AUTOSAR XML (schema 4-2-2)
package /COM_SWC
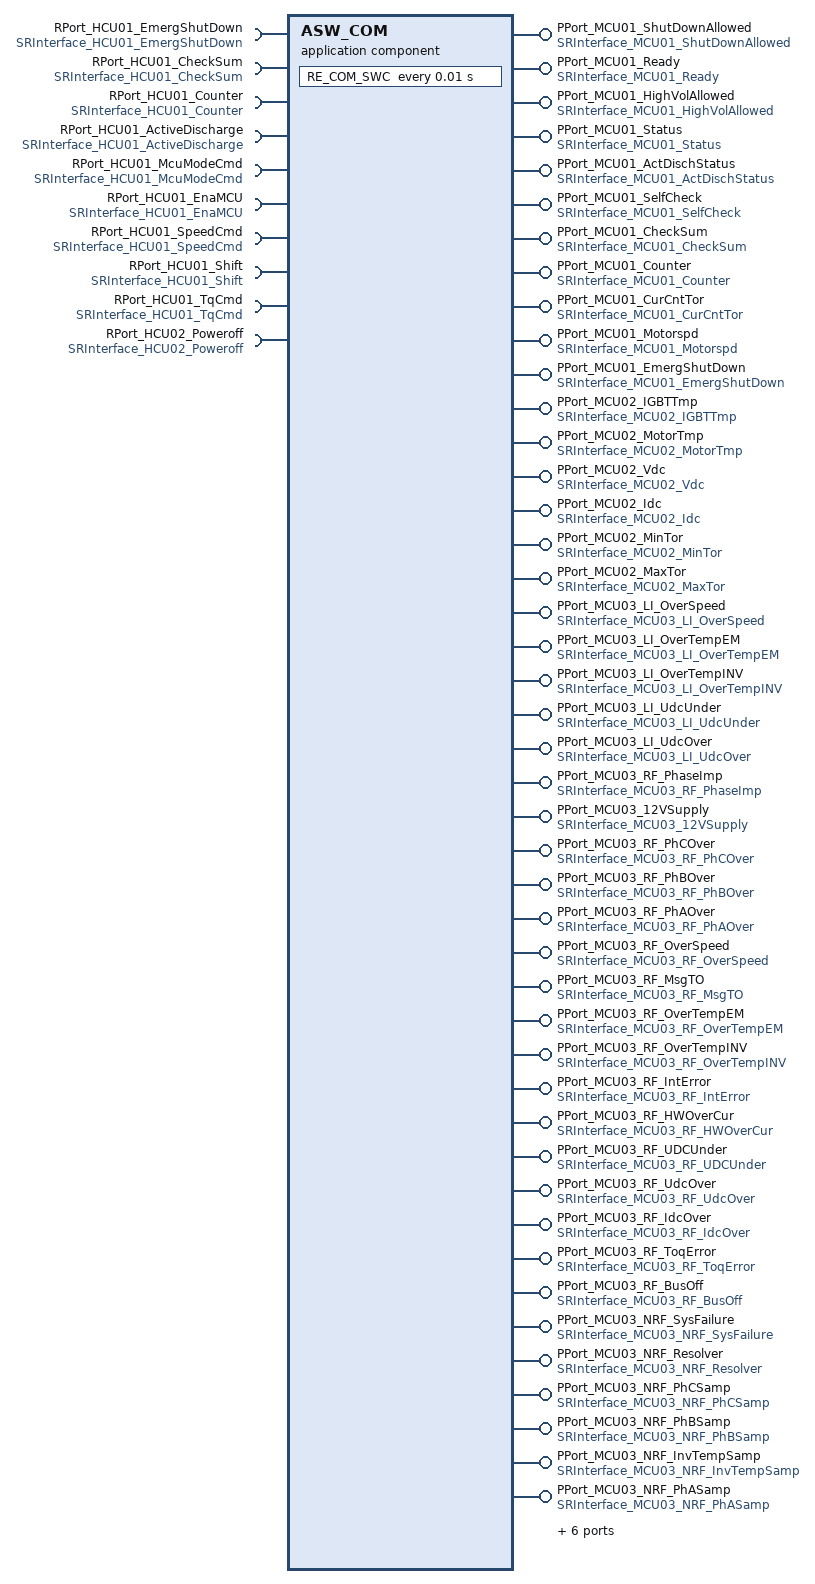
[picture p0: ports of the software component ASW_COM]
  application sw component type ASW_COM
    10 x require port:
      RPort_HCU01_EmergShutDown: nonqueued-receiver-com-spec{data-element=HCU01_EmergShutDown, alive-timeout=0.5}, required-interface=SRInterface_HCU01_EmergShutDown
      RPort_HCU01_CheckSum: nonqueued-receiver-com-spec{data-element=HCU01_CheckSum, alive-timeout=0.5}, required-interface=SRInterface_HCU01_CheckSum
      RPort_HCU01_Counter: nonqueued-receiver-com-spec{data-element=HCU01_Counter, alive-timeout=0.5}, required-interface=SRInterface_HCU01_Counter
      RPort_HCU01_ActiveDischarge: nonqueued-receiver-com-spec{data-element=HCU01_ActiveDischarge, alive-timeout=0.5}, required-interface=SRInterface_HCU01_ActiveDischarge
      RPort_HCU01_McuModeCmd: nonqueued-receiver-com-spec{data-element=HCU01_McuModeCmd, alive-timeout=0.5}, required-interface=SRInterface_HCU01_McuModeCmd
      RPort_HCU01_EnaMCU: nonqueued-receiver-com-spec{data-element=HCU01_EnaMCU, alive-timeout=0.5}, required-interface=SRInterface_HCU01_EnaMCU
      RPort_HCU01_SpeedCmd: nonqueued-receiver-com-spec{data-element=HCU01_SpeedCmd, alive-timeout=0.5}, required-interface=SRInterface_HCU01_SpeedCmd
      RPort_HCU01_Shift: nonqueued-receiver-com-spec{data-element=HCU01_Shift, alive-timeout=0.5}, required-interface=SRInterface_HCU01_Shift
      RPort_HCU01_TqCmd: nonqueued-receiver-com-spec{data-element=HCU01_TqCmd, alive-timeout=0.5}, required-interface=SRInterface_HCU01_TqCmd
      RPort_HCU02_Poweroff: nonqueued-receiver-com-spec{data-element=HCU02_Poweroff, alive-timeout=0.5}, required-interface=SRInterface_HCU02_Poweroff
    50 x provide port:
      PPort_MCU01_ShutDownAllowed: provided-interface=SRInterface_MCU01_ShutDownAllowed
      PPort_MCU01_Ready: provided-interface=SRInterface_MCU01_Ready
      PPort_MCU01_HighVolAllowed: provided-interface=SRInterface_MCU01_HighVolAllowed
      PPort_MCU01_Status: provided-interface=SRInterface_MCU01_Status
      PPort_MCU01_ActDischStatus: provided-interface=SRInterface_MCU01_ActDischStatus
      PPort_MCU01_SelfCheck: provided-interface=SRInterface_MCU01_SelfCheck
      PPort_MCU01_CheckSum: provided-interface=SRInterface_MCU01_CheckSum
      PPort_MCU01_Counter: provided-interface=SRInterface_MCU01_Counter
      PPort_MCU01_CurCntTor: provided-interface=SRInterface_MCU01_CurCntTor
      PPort_MCU01_Motorspd: provided-interface=SRInterface_MCU01_Motorspd
      PPort_MCU01_EmergShutDown: provided-interface=SRInterface_MCU01_EmergShutDown
      PPort_MCU02_IGBTTmp: provided-interface=SRInterface_MCU02_IGBTTmp
      PPort_MCU02_MotorTmp: provided-interface=SRInterface_MCU02_MotorTmp
      PPort_MCU02_Vdc: provided-interface=SRInterface_MCU02_Vdc
      PPort_MCU02_Idc: provided-interface=SRInterface_MCU02_Idc
      PPort_MCU02_MinTor: provided-interface=SRInterface_MCU02_MinTor
      PPort_MCU02_MaxTor: provided-interface=SRInterface_MCU02_MaxTor
      PPort_MCU03_LI_OverSpeed: provided-interface=SRInterface_MCU03_LI_OverSpeed
      PPort_MCU03_LI_OverTempEM: provided-interface=SRInterface_MCU03_LI_OverTempEM
      PPort_MCU03_LI_OverTempINV: provided-interface=SRInterface_MCU03_LI_OverTempINV
      PPort_MCU03_LI_UdcUnder: provided-interface=SRInterface_MCU03_LI_UdcUnder
      PPort_MCU03_LI_UdcOver: provided-interface=SRInterface_MCU03_LI_UdcOver
      PPort_MCU03_RF_PhaseImp: provided-interface=SRInterface_MCU03_RF_PhaseImp
      PPort_MCU03_12VSupply: provided-interface=SRInterface_MCU03_12VSupply
      PPort_MCU03_RF_PhCOver: provided-interface=SRInterface_MCU03_RF_PhCOver
      PPort_MCU03_RF_PhBOver: provided-interface=SRInterface_MCU03_RF_PhBOver
      PPort_MCU03_RF_PhAOver: provided-interface=SRInterface_MCU03_RF_PhAOver
      PPort_MCU03_RF_OverSpeed: provided-interface=SRInterface_MCU03_RF_OverSpeed
      PPort_MCU03_RF_MsgTO: provided-interface=SRInterface_MCU03_RF_MsgTO
      PPort_MCU03_RF_OverTempEM: provided-interface=SRInterface_MCU03_RF_OverTempEM
      PPort_MCU03_RF_OverTempINV: provided-interface=SRInterface_MCU03_RF_OverTempINV
      PPort_MCU03_RF_IntError: provided-interface=SRInterface_MCU03_RF_IntError
      PPort_MCU03_RF_HWOverCur: provided-interface=SRInterface_MCU03_RF_HWOverCur
      PPort_MCU03_RF_UDCUnder: provided-interface=SRInterface_MCU03_RF_UDCUnder
      PPort_MCU03_RF_UdcOver: provided-interface=SRInterface_MCU03_RF_UdcOver
      PPort_MCU03_RF_IdcOver: provided-interface=SRInterface_MCU03_RF_IdcOver
      PPort_MCU03_RF_ToqError: provided-interface=SRInterface_MCU03_RF_ToqError
      PPort_MCU03_RF_BusOff: provided-interface=SRInterface_MCU03_RF_BusOff
      PPort_MCU03_NRF_SysFailure: provided-interface=SRInterface_MCU03_NRF_SysFailure
      PPort_MCU03_NRF_Resolver: provided-interface=SRInterface_MCU03_NRF_Resolver
      PPort_MCU03_NRF_PhCSamp: provided-interface=SRInterface_MCU03_NRF_PhCSamp
      PPort_MCU03_NRF_PhBSamp: provided-interface=SRInterface_MCU03_NRF_PhBSamp
      PPort_MCU03_NRF_InvTempSamp: provided-interface=SRInterface_MCU03_NRF_InvTempSamp
      PPort_MCU03_NRF_PhASamp: provided-interface=SRInterface_MCU03_NRF_PhASamp
      PPort_MCU03_NRF_DESAT: provided-interface=SRInterface_MCU03_NRF_DESAT
      PPort_MCU03_NRF_UdcSamp: provided-interface=SRInterface_MCU03_NRF_UdcSamp
      PPort_MCU03_NRF_COMError: provided-interface=SRInterface_MCU03_NRF_COMError
      PPort_MCU03_NRF_5VSupply: provided-interface=SRInterface_MCU03_NRF_5VSupply
      PPort_MCU03_NRF_EMTempSamp: provided-interface=SRInterface_MCU03_NRF_EMTempSamp
      PPort_MCU03_NRF_IdcSamp: provided-interface=SRInterface_MCU03_NRF_IdcSamp
    behavior IB_swc_COM
      timing event TE_SWC_COM_10ms: start-on-event=RE_COM_SWC, period=0.01
      runnable RE_COM_SWC: symbol=RE_COM_SWC_func
        data-receive-point-by-arguments:
          10 x access:
            DRWA_HCU01_EmergShutDown: accessed-variable=RPort_HCU01_EmergShutDown.HCU01_EmergShutDown
            DRWA_HCU01_CheckSum: accessed-variable=RPort_HCU01_CheckSum.HCU01_CheckSum
            DRWA_HCU01_Counter: accessed-variable=RPort_HCU01_Counter.HCU01_Counter
            DRWA_HCU01_ActiveDischarge: accessed-variable=RPort_HCU01_ActiveDischarge.HCU01_ActiveDischarge
            DRWA_HCU01_McuModeCmd: accessed-variable=RPort_HCU01_McuModeCmd.HCU01_McuModeCmd
            DRWA_HCU01_EnaMCU: accessed-variable=RPort_HCU01_EnaMCU.HCU01_EnaMCU
            DRWA_HCU01_SpeedCmd: accessed-variable=RPort_HCU01_SpeedCmd.HCU01_SpeedCmd
            DRWA_HCU01_Shift: accessed-variable=RPort_HCU01_Shift.HCU01_Shift
            DRWA_HCU01_TqCmd: accessed-variable=RPort_HCU01_TqCmd.HCU01_TqCmd
            DRWA_HCU02_Poweroff: accessed-variable=RPort_HCU02_Poweroff.HCU02_Poweroff
        data-send-points:
          50 x access:
            DSP_MCU01_ShutDownAllowed: accessed-variable=PPort_MCU01_ShutDownAllowed.MCU01_ShutDownAllowed
            DSP_MCU01_Ready: accessed-variable=PPort_MCU01_Ready.MCU01_Ready
            DSP_MCU01_HighVolAllowed: accessed-variable=PPort_MCU01_HighVolAllowed.MCU01_HighVolAllowed
            DSP_MCU01_Status: accessed-variable=PPort_MCU01_Status.MCU01_Status
            DSP_MCU01_ActDischStatus: accessed-variable=PPort_MCU01_ActDischStatus.MCU01_ActDischStatus
            DSP_MCU01_SelfCheck: accessed-variable=PPort_MCU01_SelfCheck.MCU01_SelfCheck
            DSP_MCU01_CheckSum: accessed-variable=PPort_MCU01_CheckSum.MCU01_CheckSum
            DSP_MCU01_Counter: accessed-variable=PPort_MCU01_Counter.MCU01_Counter
            DSP_MCU01_CurCntTor: accessed-variable=PPort_MCU01_CurCntTor.MCU01_CurCntTor
            DSP_MCU01_Motorspd: accessed-variable=PPort_MCU01_Motorspd.MCU01_Motorspd
            DSP_MCU01_EmergShutDown: accessed-variable=PPort_MCU01_EmergShutDown.MCU01_EmergShutDown
            DSP_MCU02_IGBTTmp: accessed-variable=PPort_MCU02_IGBTTmp.MCU02_IGBTTmp
            DSP_MCU02_MotorTmp: accessed-variable=PPort_MCU02_MotorTmp.MCU02_MotorTmp
            DSP_MCU02_Vdc: accessed-variable=PPort_MCU02_Vdc.MCU02_Vdc
            DSP_MCU02_Idc: accessed-variable=PPort_MCU02_Idc.MCU02_Idc
            DSP_MCU02_MinTor: accessed-variable=PPort_MCU02_MinTor.MCU02_MinTor
            DSP_MCU02_MaxTor: accessed-variable=PPort_MCU02_MaxTor.MCU02_MaxTor
            DSP_MCU03_LI_OverSpeed: accessed-variable=PPort_MCU03_LI_OverSpeed.MCU03_LI_OverSpeed
            DSP_MCU03_LI_OverTempEM: accessed-variable=PPort_MCU03_LI_OverTempEM.MCU03_LI_OverTempEM
            DSP_MCU03_LI_OverTempINV: accessed-variable=PPort_MCU03_LI_OverTempINV.MCU03_LI_OverTempINV
            DSP_MCU03_LI_UdcUnder: accessed-variable=PPort_MCU03_LI_UdcUnder.MCU03_LI_UdcUnder
            DSP_MCU03_LI_UdcOver: accessed-variable=PPort_MCU03_LI_UdcOver.MCU03_LI_UdcOver
            DSP_MCU03_RF_PhaseImp: accessed-variable=PPort_MCU03_RF_PhaseImp.MCU03_RF_PhaseImp
            DSP_MCU03_12VSupply: accessed-variable=PPort_MCU03_12VSupply.MCU03_12VSupply
            DSP_MCU03_RF_PhCOver: accessed-variable=PPort_MCU03_RF_PhCOver.MCU03_RF_PhCOver
            DSP_MCU03_RF_PhBOver: accessed-variable=PPort_MCU03_RF_PhBOver.MCU03_RF_PhBOver
            DSP_MCU03_RF_PhAOver: accessed-variable=PPort_MCU03_RF_PhAOver.MCU03_RF_PhAOver
            DSP_MCU03_RF_OverSpeed: accessed-variable=PPort_MCU03_RF_OverSpeed.MCU03_RF_OverSpeed
            DSP_MCU03_RF_MsgTO: accessed-variable=PPort_MCU03_RF_MsgTO.MCU03_RF_MsgTO
            DSP_MCU03_RF_OverTempEM: accessed-variable=PPort_MCU03_RF_OverTempEM.MCU03_RF_OverTempEM
            DSP_MCU03_RF_OverTempINV: accessed-variable=PPort_MCU03_RF_OverTempINV.MCU03_RF_OverTempINV
            DSP_MCU03_RF_IntError: accessed-variable=PPort_MCU03_RF_IntError.MCU03_RF_IntError
            DSP_MCU03_RF_HWOverCur: accessed-variable=PPort_MCU03_RF_HWOverCur.MCU03_RF_HWOverCur
            DSP_MCU03_RF_UDCUnder: accessed-variable=PPort_MCU03_RF_UDCUnder.MCU03_RF_UDCUnder
            DSP_MCU03_RF_UdcOver: accessed-variable=PPort_MCU03_RF_UdcOver.MCU03_RF_UdcOver
            DSP_MCU03_RF_IdcOver: accessed-variable=PPort_MCU03_RF_IdcOver.MCU03_RF_IdcOver
            DSP_MCU03_RF_ToqError: accessed-variable=PPort_MCU03_RF_ToqError.MCU03_RF_ToqError
            DSP_MCU03_RF_BusOff: accessed-variable=PPort_MCU03_RF_BusOff.MCU03_RF_BusOff
            DSP_MCU03_NRF_SysFailure: accessed-variable=PPort_MCU03_NRF_SysFailure.MCU03_NRF_SysFailure
            DSP_MCU03_NRF_Resolver: accessed-variable=PPort_MCU03_NRF_Resolver.MCU03_NRF_Resolver
            DSP_MCU03_NRF_PhCSamp: accessed-variable=PPort_MCU03_NRF_PhCSamp.MCU03_NRF_PhCSamp
            DSP_MCU03_NRF_PhBSamp: accessed-variable=PPort_MCU03_NRF_PhBSamp.MCU03_NRF_PhBSamp
            DSP_MCU03_NRF_InvTempSamp: accessed-variable=PPort_MCU03_NRF_InvTempSamp.MCU03_NRF_InvTempSamp
            DSP_MCU03_NRF_PhASamp: accessed-variable=PPort_MCU03_NRF_PhASamp.MCU03_NRF_PhASamp
            DSP_MCU03_NRF_DESAT: accessed-variable=PPort_MCU03_NRF_DESAT.MCU03_NRF_DESAT
            DSP_MCU03_NRF_UdcSamp: accessed-variable=PPort_MCU03_NRF_UdcSamp.MCU03_NRF_UdcSamp
            DSP_MCU03_NRF_COMError: accessed-variable=PPort_MCU03_NRF_COMError.MCU03_NRF_COMError
            DSP_MCU03_NRF_5VSupply: accessed-variable=PPort_MCU03_NRF_5VSupply.MCU03_NRF_5VSupply
            DSP_MCU03_NRF_EMTempSamp: accessed-variable=PPort_MCU03_NRF_EMTempSamp.MCU03_NRF_EMTempSamp
            DSP_MCU03_NRF_IdcSamp: accessed-variable=PPort_MCU03_NRF_IdcSamp.MCU03_NRF_IdcSamp
  60 x sender receiver interface:
    SRInterface_HCU01_EmergShutDown
      data HCU01_EmergShutDown: type=uint8
    SRInterface_HCU01_CheckSum
      data HCU01_CheckSum: type=uint8
    SRInterface_HCU01_Counter
      data HCU01_Counter: type=uint8
    SRInterface_HCU01_ActiveDischarge
      data HCU01_ActiveDischarge: type=uint8
    SRInterface_HCU01_McuModeCmd
      data HCU01_McuModeCmd: type=uint8
    SRInterface_HCU01_EnaMCU
      data HCU01_EnaMCU: type=uint8
    SRInterface_HCU01_SpeedCmd
      data HCU01_SpeedCmd: type=uint16
    SRInterface_HCU01_Shift
      data HCU01_Shift: type=uint8
    SRInterface_HCU01_TqCmd
      data HCU01_TqCmd: type=uint16
    SRInterface_HCU02_Poweroff
      data HCU02_Poweroff: type=uint8
    SRInterface_MCU01_ShutDownAllowed
      data MCU01_ShutDownAllowed: type=uint8
    SRInterface_MCU01_Ready
      data MCU01_Ready: type=uint8
    SRInterface_MCU01_HighVolAllowed
      data MCU01_HighVolAllowed: type=uint8
    SRInterface_MCU01_Status
      data MCU01_Status: type=uint8
    SRInterface_MCU01_ActDischStatus
      data MCU01_ActDischStatus: type=uint8
    SRInterface_MCU01_SelfCheck
      data MCU01_SelfCheck: type=uint8
    SRInterface_MCU01_CheckSum
      data MCU01_CheckSum: type=uint8
    SRInterface_MCU01_Counter
      data MCU01_Counter: type=uint8
    SRInterface_MCU01_CurCntTor
      data MCU01_CurCntTor: type=uint16
    SRInterface_MCU01_Motorspd
      data MCU01_Motorspd: type=uint16
    SRInterface_MCU01_EmergShutDown
      data MCU01_EmergShutDown: type=uint8
    SRInterface_MCU02_IGBTTmp
      data MCU02_IGBTTmp: type=uint8
    SRInterface_MCU02_MotorTmp
      data MCU02_MotorTmp: type=uint8
    SRInterface_MCU02_Vdc
      data MCU02_Vdc: type=uint16
    SRInterface_MCU02_Idc
      data MCU02_Idc: type=uint16
    SRInterface_MCU02_MinTor
      data MCU02_MinTor: type=uint16
    SRInterface_MCU02_MaxTor
      data MCU02_MaxTor: type=uint16
    SRInterface_MCU03_LI_OverSpeed
      data MCU03_LI_OverSpeed: type=uint8
    SRInterface_MCU03_LI_OverTempEM
      data MCU03_LI_OverTempEM: type=uint8
    SRInterface_MCU03_LI_OverTempINV
      data MCU03_LI_OverTempINV: type=uint8
    SRInterface_MCU03_LI_UdcUnder
      data MCU03_LI_UdcUnder: type=uint8
    SRInterface_MCU03_LI_UdcOver
      data MCU03_LI_UdcOver: type=uint8
    SRInterface_MCU03_RF_PhaseImp
      data MCU03_RF_PhaseImp: type=uint8
    SRInterface_MCU03_12VSupply
      data MCU03_12VSupply: type=uint8
    SRInterface_MCU03_RF_PhCOver
      data MCU03_RF_PhCOver: type=uint8
    SRInterface_MCU03_RF_PhBOver
      data MCU03_RF_PhBOver: type=uint8
    SRInterface_MCU03_RF_PhAOver
      data MCU03_RF_PhAOver: type=uint8
    SRInterface_MCU03_RF_OverSpeed
      data MCU03_RF_OverSpeed: type=uint8
    SRInterface_MCU03_RF_MsgTO
      data MCU03_RF_MsgTO: type=uint8
    SRInterface_MCU03_RF_OverTempEM
      data MCU03_RF_OverTempEM: type=uint8
    SRInterface_MCU03_RF_OverTempINV
      data MCU03_RF_OverTempINV: type=uint8
    SRInterface_MCU03_RF_IntError
      data MCU03_RF_IntError: type=uint8
    SRInterface_MCU03_RF_HWOverCur
      data MCU03_RF_HWOverCur: type=uint8
    SRInterface_MCU03_RF_UDCUnder
      data MCU03_RF_UDCUnder: type=uint8
    SRInterface_MCU03_RF_UdcOver
      data MCU03_RF_UdcOver: type=uint8
    SRInterface_MCU03_RF_IdcOver
      data MCU03_RF_IdcOver: type=uint8
    SRInterface_MCU03_RF_ToqError
      data MCU03_RF_ToqError: type=uint8
    SRInterface_MCU03_RF_BusOff
      data MCU03_RF_BusOff: type=uint8
    SRInterface_MCU03_NRF_SysFailure
      data MCU03_NRF_SysFailure: type=uint8
    SRInterface_MCU03_NRF_Resolver
      data MCU03_NRF_Resolver: type=uint8
    SRInterface_MCU03_NRF_PhCSamp
      data MCU03_NRF_PhCSamp: type=uint8
    SRInterface_MCU03_NRF_PhBSamp
      data MCU03_NRF_PhBSamp: type=uint8
    SRInterface_MCU03_NRF_InvTempSamp
      data MCU03_NRF_InvTempSamp: type=uint8
    SRInterface_MCU03_NRF_PhASamp
      data MCU03_NRF_PhASamp: type=uint8
    SRInterface_MCU03_NRF_DESAT
      data MCU03_NRF_DESAT: type=uint8
    SRInterface_MCU03_NRF_UdcSamp
      data MCU03_NRF_UdcSamp: type=uint8
    SRInterface_MCU03_NRF_COMError
      data MCU03_NRF_COMError: type=uint8
    SRInterface_MCU03_NRF_5VSupply
      data MCU03_NRF_5VSupply: type=uint8
    SRInterface_MCU03_NRF_EMTempSamp
      data MCU03_NRF_EMTempSamp: type=uint8
    SRInterface_MCU03_NRF_IdcSamp
      data MCU03_NRF_IdcSamp: type=uint8
  port interface mapping set PortInterfaceMappingSet_0
